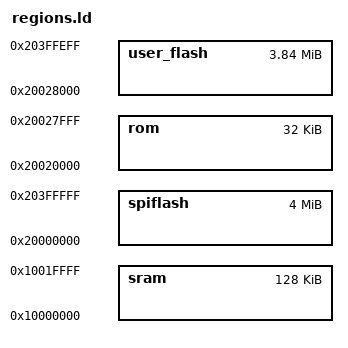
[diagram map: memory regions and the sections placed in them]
MEMORY {
	spiflash : ORIGIN = 0x20000000, LENGTH = 0x00400000
	rom : ORIGIN = 0x20020000, LENGTH = 0x00008000
	sram : ORIGIN = 0x10000000, LENGTH = 0x00020000
	user_flash : ORIGIN = 0x20028000, LENGTH = 0x003d7f00
}
